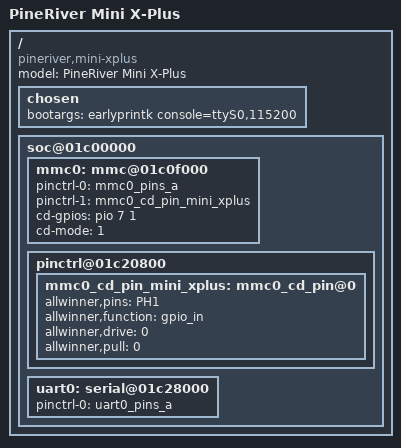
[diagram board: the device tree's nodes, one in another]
/*
 * Copyright 2012 Maxime Ripard
 *
 * Maxime Ripard <maxime.ripard@free-electrons.com>
 *
 * The code contained herein is licensed under the GNU General Public
 * License. You may obtain a copy of the GNU General Public License
 * Version 2 or later at the following locations:
 *
 * http://www.opensource.org/licenses/gpl-license.html
 * http://www.gnu.org/copyleft/gpl.html
 */

/dts-v1/;
/include/ "sun4i-a10.dtsi"

/ {
	model = "PineRiver Mini X-Plus";
	compatible = "pineriver,mini-xplus", "allwinner,sun4i-a10";

	chosen {
		bootargs = "earlyprintk console=ttyS0,115200";
	};

	soc@01c00000 {
		mmc0: mmc@01c0f000 {
			pinctrl-names = "default";
			pinctrl-0 = <&mmc0_pins_a>;
			pinctrl-1 = <&mmc0_cd_pin_mini_xplus>;
			cd-gpios = <&pio 7 1 0>; /* PH1 */
			cd-mode = <1>;
			status = "okay";
		};

		pinctrl@01c20800 {
			mmc0_cd_pin_mini_xplus: mmc0_cd_pin@0 {
				allwinner,pins = "PH1";
				allwinner,function = "gpio_in";
				allwinner,drive = <0>;
				allwinner,pull = <0>;
			};
		};

		uart0: serial@01c28000 {
			pinctrl-names = "default";
			pinctrl-0 = <&uart0_pins_a>;
			status = "okay";
		};
	};
};
